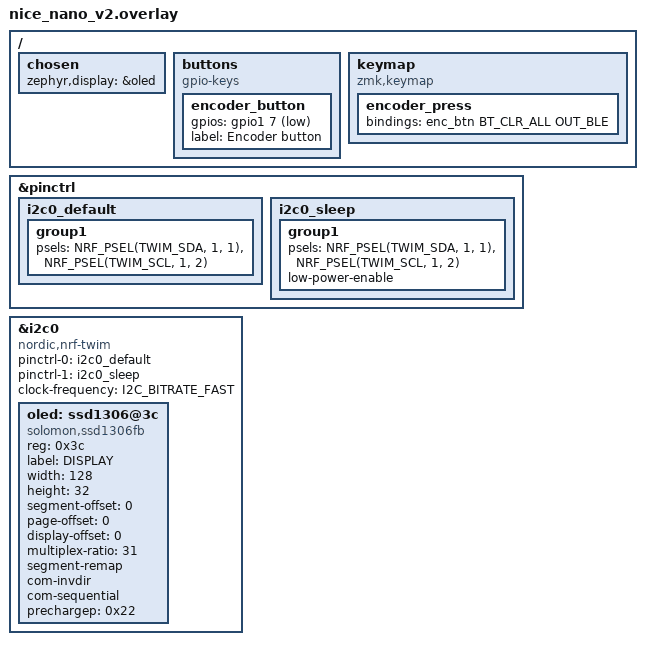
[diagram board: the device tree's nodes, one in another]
&pinctrl {
    i2c0_default: i2c0_default {
        group1 {
            psels = <NRF_PSEL(TWIM_SDA, 1, 1)>,
                    <NRF_PSEL(TWIM_SCL, 1, 2)>;
        };
    };

    i2c0_sleep: i2c0_sleep {
        group1 {
            psels = <NRF_PSEL(TWIM_SDA, 1, 1)>,
                    <NRF_PSEL(TWIM_SCL, 1, 2)>;
            low-power-enable;
        };
    };
};

&i2c0 {
    status = "okay";
    compatible = "nordic,nrf-twim";
    pinctrl-0 = <&i2c0_default>;
    pinctrl-1 = <&i2c0_sleep>;
    pinctrl-names = "default", "sleep";
    clock-frequency = <I2C_BITRATE_FAST>;

    oled: ssd1306@3c {
        compatible = "solomon,ssd1306fb";
        reg = <0x3c>;
        label = "DISPLAY";
        width = <128>;
        height = <32>;
        segment-offset = <0>;
        page-offset = <0>;
        display-offset = <0>;
        multiplex-ratio = <31>;
        segment-remap;
        com-invdir;
        com-sequential;
        prechargep = <0x22>;
    };
};

/ {
    chosen {
        zephyr,display = &oled;
    };

    // Encoder button configuration
    buttons {
        compatible = "gpio-keys";
        encoder_button: encoder_button {
            gpios = <&gpio1 7 (GPIO_ACTIVE_LOW | GPIO_PULL_UP)>; // P1.07
            label = "Encoder button";
        };
    };

    // Key bindings for encoder button
    keymap {
        compatible = "zmk,keymap";
        encoder_press {
            bindings = <&enc_btn BT_CLR_ALL OUT_BLE>;
        };
    };
};
